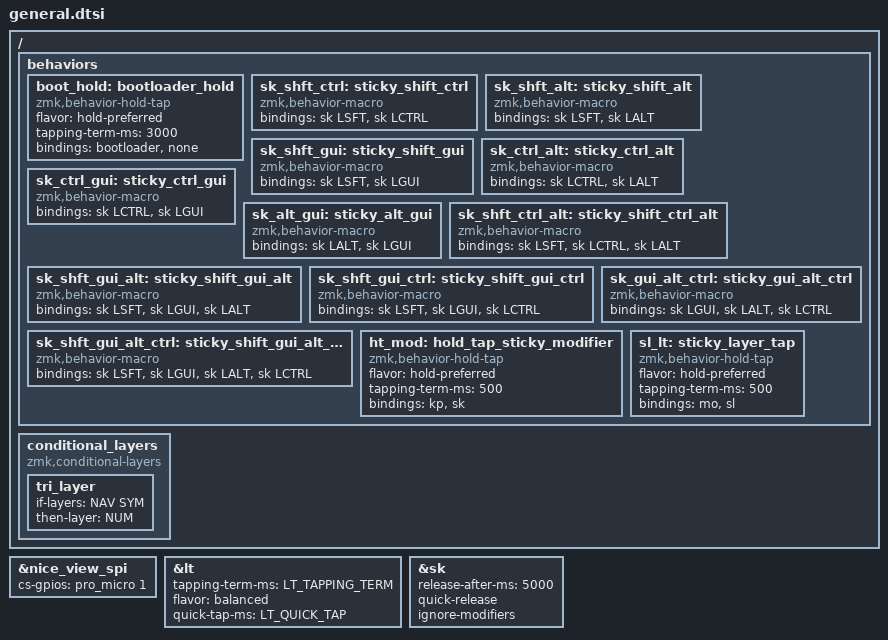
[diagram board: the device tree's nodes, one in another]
#define DEF 0
#define NAV 1
#define SYM 2
#define NUM 3
#define SCR 4
#define MOD 5 

#define LT_TAPPING_TERM 240
#define LT_QUICK_TAP 175

/* Keyboard layout key positions
-------------------------------                  -------------------------------
|  0 |  1 |  2 |  3 | 4  |  5 |                  |  6 |  7 |  8 |  9 | 10 | 11 |
-------------------------------                  -------------------------------
| 12 | 13 | 14 | 15 | 16 | 17 |                  | 18 | 19 | 20 | 21 | 22 | 23 |
-------------------------------                  -------------------------------
| 24 | 25 | 26 | 27 | 28 | 29 |                  | 30 | 31 | 32 | 33 | 34 | 35 |
--------------------------------------   ---------------------------------------
          | 36 | 37 |  | 38 | 39 |40 |   | 41 | 42 |                 | 43 |
          -----------  ---------------   -----------                 ------
*/

// nice!view display configuration
&nice_view_spi { cs-gpios = <&pro_micro 1 GPIO_ACTIVE_HIGH>; };

// Timing configuration for layer-tap
&lt {
    tapping-term-ms = <LT_TAPPING_TERM>;
    flavor = "balanced";
    quick-tap-ms = <LT_QUICK_TAP>;
};

// Sticky key configuration for one-shot modifiers
&sk {
    release-after-ms = <5000>;
    quick-release;
    ignore-modifiers;
};

/ {
    behaviors {
        boot_hold: bootloader_hold {
            compatible = "zmk,behavior-hold-tap";
            #binding-cells = <2>;
            flavor = "hold-preferred";
            tapping-term-ms = <3000>;
            bindings = <&bootloader>, <&none>;
        };

        sk_shft_ctrl: sticky_shift_ctrl {
            compatible = "zmk,behavior-macro";
            #binding-cells = <0>;
            bindings = <&sk LSFT>, <&sk LCTRL>;
        };

        sk_shft_alt: sticky_shift_alt {
            compatible = "zmk,behavior-macro";
            #binding-cells = <0>;
            bindings = <&sk LSFT>, <&sk LALT>;
        };

        sk_shft_gui: sticky_shift_gui {
            compatible = "zmk,behavior-macro";
            #binding-cells = <0>;
            bindings = <&sk LSFT>, <&sk LGUI>;
        };

        sk_ctrl_alt: sticky_ctrl_alt {
            compatible = "zmk,behavior-macro";
            #binding-cells = <0>;
            bindings = <&sk LCTRL>, <&sk LALT>;
        };

        sk_ctrl_gui: sticky_ctrl_gui {
            compatible = "zmk,behavior-macro";
            #binding-cells = <0>;
            bindings = <&sk LCTRL>, <&sk LGUI>;
        };

        sk_alt_gui: sticky_alt_gui {
            compatible = "zmk,behavior-macro";
            #binding-cells = <0>;
            bindings = <&sk LALT>, <&sk LGUI>;
        };

        sk_shft_ctrl_alt: sticky_shift_ctrl_alt {
            compatible = "zmk,behavior-macro";
            #binding-cells = <0>;
            bindings = <&sk LSFT>, <&sk LCTRL>, <&sk LALT>;
        };

        sk_shft_gui_alt: sticky_shift_gui_alt {
            compatible = "zmk,behavior-macro";
            #binding-cells = <0>;
            bindings = <&sk LSFT>, <&sk LGUI>, <&sk LALT>;
        };

        sk_shft_gui_ctrl: sticky_shift_gui_ctrl {
            compatible = "zmk,behavior-macro";
            #binding-cells = <0>;
            bindings = <&sk LSFT>, <&sk LGUI>, <&sk LCTRL>;
        };

        sk_gui_alt_ctrl: sticky_gui_alt_ctrl {
            compatible = "zmk,behavior-macro";
            #binding-cells = <0>;
            bindings = <&sk LGUI>, <&sk LALT>, <&sk LCTRL>;
        };

        sk_shft_gui_alt_ctrl: sticky_shift_gui_alt_ctrl {
            compatible = "zmk,behavior-macro";
            #binding-cells = <0>;
            bindings = <&sk LSFT>, <&sk LGUI>, <&sk LALT>, <&sk LCTRL>;
        };

        ht_mod: hold_tap_sticky_modifier {
            compatible = "zmk,behavior-hold-tap";
            #binding-cells = <2>;
            flavor = "hold-preferred";
            tapping-term-ms = <500>;
            bindings = <&kp>, <&sk>;
        };

        // Sticky layer tap: hold for momentary layer, tap for one-shot layer
        // Layer deactivates after pressing any key, but held modifiers remain active
        sl_lt: sticky_layer_tap {
            compatible = "zmk,behavior-hold-tap";
            #binding-cells = <2>;
            flavor = "hold-preferred";
            tapping-term-ms = <500>;
            bindings = <&mo>, <&sl>;
        };
    };

    // Tri-layer: NUM activates when both NAV and SYM are held
    conditional_layers {
        compatible = "zmk,conditional-layers";
        tri_layer {
            if-layers = <NAV SYM>;
            then-layer = <NUM>;
        };
    };
};
